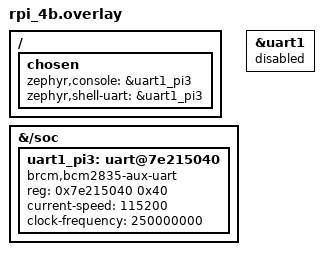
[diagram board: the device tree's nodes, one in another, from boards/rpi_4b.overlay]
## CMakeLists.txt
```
cmake_minimum_required(VERSION 3.20.0)

find_package(Zephyr REQUIRED HINTS $ENV{ZEPHYR_BASE})
project(rpi3_ethernet_dma)

target_sources(app PRIVATE src/main.c)
```

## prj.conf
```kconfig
# Core Networking Options
CONFIG_NETWORKING=y
CONFIG_NET_IPV4=y
CONFIG_NET_UDP=y
CONFIG_NET_TCP=y

# Layer 2 / ARP Management
CONFIG_NET_L2_ETHERNET=y
CONFIG_NET_ARP=y

# Explicitly enable the Intel E1000 Driver for QEMU emulation
CONFIG_ETH_E1000=y

# Network buffer configurations to prevent packet drops
CONFIG_NET_PKT_RX_COUNT=16
CONFIG_NET_PKT_TX_COUNT=16
CONFIG_NET_BUF_RX_COUNT=64
CONFIG_NET_BUF_TX_COUNT=64

# Updated Logging Structure
CONFIG_NET_LOG=y

# Disable DHCPv4 Client
CONFIG_NET_DHCPV4=n

# Virtual Ethernet Driver Interface for QEMU simulation
CONFIG_NET_QEMU_ETHERNET=y
CONFIG_ENTROPY_GENERATOR=y
CONFIG_TEST_RANDOM_GENERATOR=y
```

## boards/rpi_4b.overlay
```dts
/ {
	chosen {
		zephyr,console = &uart1_pi3;
		zephyr,shell-uart = &uart1_pi3;
	};
};

/* This is the correct way to modify an existing absolute path node */
&{/soc} {
	/* Override BCM2711 peripheral base to Pi 3's BCM2837 base (0x3F000000) */
	ranges = <0x7e000000 0x3f000000 0x01000000>;

	uart1_pi3: uart@7e215040 {
		compatible = "brcm,bcm2835-aux-uart";
		reg = <0x7e215040 0x40>;
		status = "okay";
		current-speed = <115200>;
		clock-frequency = <250000000>;
	};
};

/* Disable the original Pi 4 default UART definition */
&uart1 {
	status = "disabled";
};
```

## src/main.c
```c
#include <zephyr/kernel.h>
#include <zephyr/logging/log.h>
#include <zephyr/net/net_if.h>
#include <zephyr/net/net_ip.h>

LOG_MODULE_REGISTER(rpi3_boot, LOG_LEVEL_INF);

void main(void)
{
    LOG_INF("------------------------------------------------");
    LOG_INF("Zephyr RTOS Booted Successfully on QEMU!");
    LOG_INF("------------------------------------------------");

    /* Wait a moment for the virtual hardware driver to settle */
    k_sleep(K_MSEC(500));

    struct net_if *iface = net_if_get_default();
    
    if (iface) {
        struct in_addr local_addr;
        struct in_addr netmask;
        struct net_if_addr *ifaddr;

        /* 1. Parse and assign the static IP address */
        if (net_addr_pton(AF_INET, "192.168.192.2", &local_addr) == 0) {
            ifaddr = net_if_ipv4_addr_add(iface, &local_addr, NET_ADDR_MANUAL, 0);
            if (ifaddr) {
                LOG_INF("Static IP Assigned Successfully: 192.168.192.2");
            } else {
                LOG_ERR("Failed to assign static IP address slot!");
            }
        }

        /* 2. Parse and assign the Netmask (255.255.255.0 / Subnet /24) */
        if (net_addr_pton(AF_INET, "255.255.255.0", &netmask) == 0) {
            if (net_if_ipv4_set_netmask_by_addr(iface, &local_addr, &netmask)) {
                LOG_INF("Netmask Set Successfully: 255.255.255.0");
            } else {
                LOG_ERR("Failed to set netmask!");
            }
        }

        /* 3. Explicitly administrative up-state shift */
        net_if_up(iface);
        LOG_INF("Network interface explicitly brought UP.");

    } else {
        LOG_ERR("No default network interface found!");
    }

    while (1) {
        LOG_INF("Alive and waiting for network steps...");
        k_sleep(K_SECONDS(5));
    }
}
```
